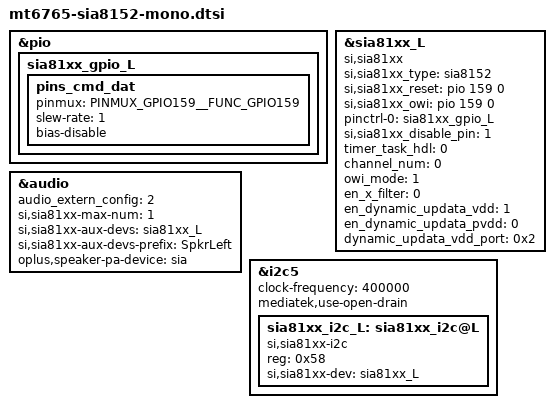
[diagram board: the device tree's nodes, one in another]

/* Copyright (c) 2018, The Linux Foundation. All rights reserved.
 *
 * This program is free software; you can redistribute it and/or modify
 * it under the terms of the GNU General Public License version 2 and
 * only version 2 as published by the Free Software Foundation.
 *
 * This program is distributed in the hope that it will be useful,
 * but WITHOUT ANY WARRANTY; without even the implied warranty of
 * MERCHANTABILITY or FITNESS FOR A PARTICULAR PURPOSE.  See the
 * GNU General Public License for more details.
 */

&pio {
	sia81xx_gpio_L: sia81xx_gpio_L {
		pins_cmd_dat {
			pinmux = <PINMUX_GPIO159__FUNC_GPIO159>;

			slew-rate = <1>;
			bias-disable;
		};
	};
};


&sia81xx_L {
	compatible = "si,sia81xx";
	si,sia81xx_type = "sia8152";
	si,sia81xx_reset = <&pio 159 0>;
	si,sia81xx_owi = <&pio 159 0>;
	pinctrl-names = "sia81xx_gpio";
	pinctrl-0 = <&sia81xx_gpio_L>;

	si,sia81xx_disable_pin = <1>;

	/* the same value share a same task
	 * valid value range : 0 ~ 7 */
	timer_task_hdl = <0>;

	channel_num = <0>;
	owi_mode = <1>;
	en_x_filter = <0>;
	en_dynamic_updata_vdd = <1>;
	en_dynamic_updata_pvdd = <0>;
	dynamic_updata_vdd_port = <0x2>;
};


&audio {
	/* this dtsi config for product's special config, AudioHal read ctl 'OPLUS_AUDIO_EXTERN_CONFIG' get the values*
	 * 1st value --> PA type: 0:NXP Pa, 1:Awinic Pa 2:sia81xx Pa*/
	audio_extern_config = <2>;
	si,sia81xx-max-num = <1>;
	si,sia81xx-aux-devs = <&sia81xx_L>;
	si,sia81xx-aux-devs-prefix = "SpkrLeft";
	oplus,speaker-pa-device = "sia";
};

&i2c5 {
	#address-cells = <1>;
	#size-cells = <0>;
	clock-frequency = <400000>;
	mediatek,use-open-drain;

	sia81xx_i2c_L: sia81xx_i2c@L {
		compatible = "si,sia81xx-i2c";
		reg = <0x58>;
		si,sia81xx-dev = <&sia81xx_L>;
	};
};
